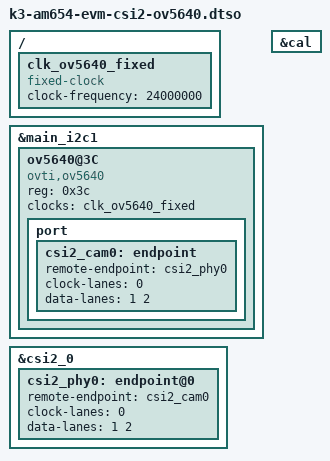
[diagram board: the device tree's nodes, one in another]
// SPDX-License-Identifier: GPL-2.0
/*
 * Copyright (C) 2019 Texas Instruments Incorporated - http://www.ti.com/
 */

/dts-v1/;
/plugin/;
#include <dt-bindings/gpio/gpio.h>

/ {
  fragment@101 {
	target-path = "/";

	__overlay__ {
		clk_ov5640_fixed: clk_ov5640_fixed {
			compatible = "fixed-clock";
			#clock-cells = <0>;
			clock-frequency = <24000000>;
		};
	};
  };
};

&main_i2c1 {
	#address-cells = <1>;
	#size-cells = <0>;

	ov5640@3C {
		compatible = "ovti,ov5640";
		reg = <0x3c>;

		clocks = <&clk_ov5640_fixed>;
		clock-names = "xclk";

		port {
			csi2_cam0: endpoint {
				remote-endpoint = <&csi2_phy0>;
				clock-lanes = <0>;
				data-lanes = <1 2>;
			};
		};
	};
};

&cal {
	status = "okay";
};

&csi2_0 {
	csi2_phy0: endpoint@0 {
		remote-endpoint = <&csi2_cam0>;
		clock-lanes = <0>;
		data-lanes = <1 2>;
	};
};
